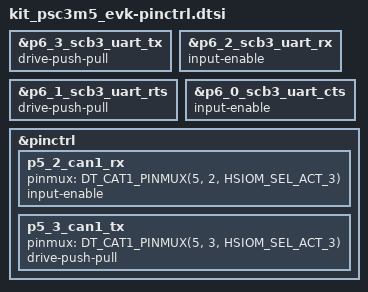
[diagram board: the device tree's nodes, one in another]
/*
 * Copyright (c) 2025 Cypress Semiconductor Corporation.
 * SPDX-License-Identifier: Apache-2.0
 */

/* Configure pin drive mode for uart pins */
&p6_3_scb3_uart_tx {
	drive-push-pull;
};

&p6_2_scb3_uart_rx {
	input-enable;
};

&p6_1_scb3_uart_rts {
	drive-push-pull;
};

&p6_0_scb3_uart_cts {
	input-enable;
};

&pinctrl {

	/omit-if-no-ref/ p5_2_can1_rx: p5_2_can1_rx {
		pinmux = <DT_CAT1_PINMUX(5, 2, HSIOM_SEL_ACT_3)>;
		input-enable;
	};

	/omit-if-no-ref/ p5_3_can1_tx: p5_3_can1_tx {
		pinmux = <DT_CAT1_PINMUX(5, 3, HSIOM_SEL_ACT_3)>;
		drive-push-pull;
	};
};
